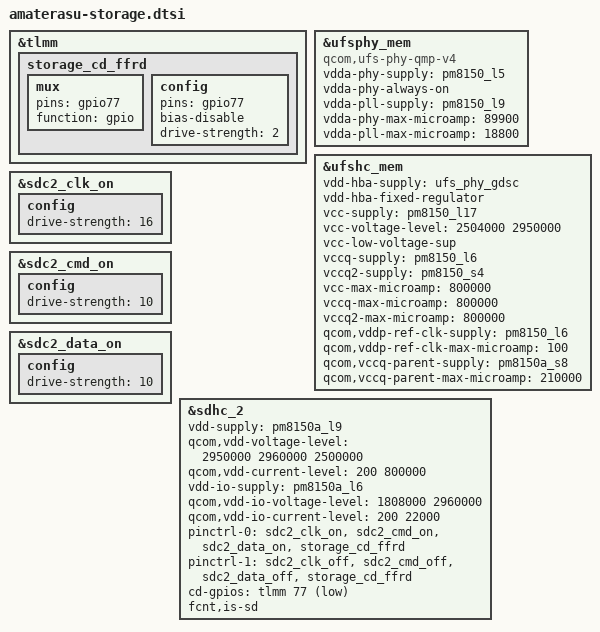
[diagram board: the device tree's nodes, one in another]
/*
 * FCNT arrows 5G (F-51A) - Storage: UFS supplies and SD card slot (SDHC2) pins and card detect.
 *
 * Reconstructed from the FCNT stock dtbo (kona FFRD REV7 SKU3); FFRD is
 * derived from the CLO kona QRD board files.
 */

&tlmm {
	storage_cd_ffrd: storage_cd_ffrd {
		mux {
			pins = "gpio77";
			function = "gpio";
		};

		config {
			pins = "gpio77";
			bias-disable;
			drive-strength = <2>;
		};
	};
};

&ufsphy_mem {
	compatible = "qcom,ufs-phy-qmp-v4";
	vdda-phy-supply = <&pm8150_l5>;
	vdda-phy-always-on;
	vdda-pll-supply = <&pm8150_l9>;
	vdda-phy-max-microamp = <89900>;
	vdda-pll-max-microamp = <18800>;
	status = "ok";
};

&ufshc_mem {
	vdd-hba-supply = <&ufs_phy_gdsc>;
	vdd-hba-fixed-regulator;
	vcc-supply = <&pm8150_l17>;
	vcc-voltage-level = <2504000 2950000>;
	vcc-low-voltage-sup;
	vccq-supply = <&pm8150_l6>;
	vccq2-supply = <&pm8150_s4>;
	vcc-max-microamp = <800000>;
	vccq-max-microamp = <800000>;
	vccq2-max-microamp = <800000>;
	qcom,vddp-ref-clk-supply = <&pm8150_l6>;
	qcom,vddp-ref-clk-max-microamp = <100>;
	qcom,vccq-parent-supply = <&pm8150a_s8>;
	qcom,vccq-parent-max-microamp = <210000>;
	status = "ok";
};

&sdc2_clk_on {
	config {
		drive-strength = <16>;
	};
};

&sdc2_cmd_on {
	config {
		drive-strength = <10>;
	};
};

&sdc2_data_on {
	config {
		drive-strength = <10>;
	};
};

&sdhc_2 {
	vdd-supply = <&pm8150a_l9>;
	qcom,vdd-voltage-level = <2950000 2960000 2500000>;
	qcom,vdd-current-level = <200 800000>;
	vdd-io-supply = <&pm8150a_l6>;
	qcom,vdd-io-voltage-level = <1808000 2960000>;
	qcom,vdd-io-current-level = <200 22000>;
	pinctrl-names = "active", "sleep";
	pinctrl-0 = <&sdc2_clk_on &sdc2_cmd_on &sdc2_data_on &storage_cd_ffrd>;
	pinctrl-1 = <&sdc2_clk_off &sdc2_cmd_off &sdc2_data_off &storage_cd_ffrd>;
	cd-gpios = <&tlmm 77 1>;
	fcnt,is-sd;
	status = "ok";
};
